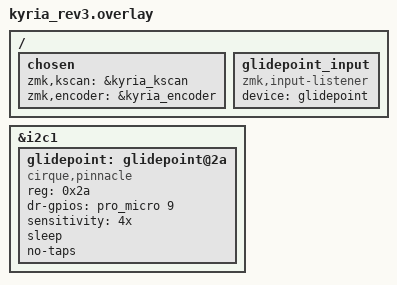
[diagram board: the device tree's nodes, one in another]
/ {
    chosen {
        zmk,kscan = &kyria_kscan;
        zmk,encoder = &kyria_encoder;
    };

    glidepoint_input {
        compatible = "zmk,input-listener";
        device = <&glidepoint>;

        // Optional settings you can uncomment as needed
        // xy-swap;
        // y-invert;
        // x-invert;
    };
};

&i2c1 {
    status = "okay";
    
    glidepoint: glidepoint@2a {
        compatible = "cirque,pinnacle";
        reg = <0x2a>;  // I2C address of the trackpad
        status = "okay";
        dr-gpios = <&pro_micro 9 (GPIO_ACTIVE_HIGH)>;  // Data ready pin
        sensitivity = "4x";
        sleep;
        no-taps;
    };
};
